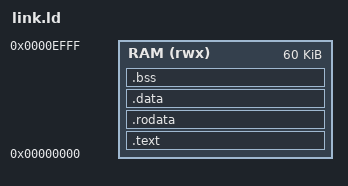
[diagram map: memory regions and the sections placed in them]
/* Firmware in the block RAM at address 0, below the boot loader at 0xF000
 * (BOOT_BASE in hw.h; ADR-0011). */
ENTRY(_start)
MEMORY { RAM (rwx) : ORIGIN = 0x00000000, LENGTH = 60K }

SECTIONS
{
    .text : { KEEP(*(.text.start)) *(.text*) } > RAM
    .rodata : { *(.rodata*) *(.srodata*) } > RAM
    .data : { *(.data*) *(.sdata*) } > RAM
    .bss (NOLOAD) : {
        . = ALIGN(4);
        _bss_start = .;
        *(.bss*) *(.sbss*) *(COMMON)
        . = ALIGN(4);
        _bss_end = .;
    } > RAM
    _stack_top = ORIGIN(RAM) + LENGTH(RAM);
}
